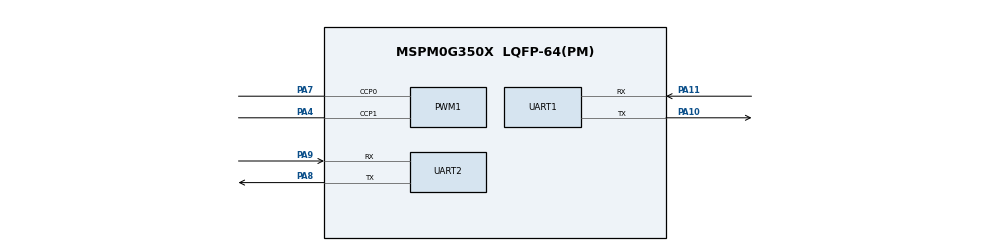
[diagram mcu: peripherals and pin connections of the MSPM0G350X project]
/**
 * @cliArgs --device "MSPM0G350X" --part "Default" --package "LQFP-64(PM)" --product "mspm0_sdk@2.10.00.04"
 * @versions {"tool":"1.27.0+4565"}
 */

/**
 * Import the modules used in this configuration.
 */
const GPIO    = scripting.addModule("/ti/driverlib/GPIO", {}, false);
const GPIO1   = GPIO.addInstance();
const GPIO2   = GPIO.addInstance();
const GPIO3   = GPIO.addInstance();
const GPIO4   = GPIO.addInstance();
const PWM     = scripting.addModule("/ti/driverlib/PWM", {}, false);
const PWM1    = PWM.addInstance();
const SYSCTL  = scripting.addModule("/ti/driverlib/SYSCTL");
const SYSTICK = scripting.addModule("/ti/driverlib/SYSTICK");
const TIMER   = scripting.addModule("/ti/driverlib/TIMER", {}, false);
const TIMER1  = TIMER.addInstance();
const UART    = scripting.addModule("/ti/driverlib/UART", {}, false);
const UART1   = UART.addInstance();
const UART2   = UART.addInstance();

/**
 * Write custom configuration values to the imported modules.
 */
const divider6       = system.clockTree["PLL_CLK2X_DIV"];
divider6.divideValue = 4;

const divider7       = system.clockTree["PLL_PDIV"];
divider7.divideValue = 2;

const divider9       = system.clockTree["UDIV"];
divider9.divideValue = 2;

const gate7  = system.clockTree["MFCLKGATE"];
gate7.enable = true;

const multiplier2         = system.clockTree["PLL_QDIV"];
multiplier2.multiplyValue = 10;

const mux8       = system.clockTree["HSCLKMUX"];
mux8.inputSelect = "HSCLKMUX_SYSPLL2X";

GPIO1.$name                              = "GPIO_BEEP";
GPIO1.port                               = "PORTA";
GPIO1.associatedPins[0].$name            = "USER_BEEP";
GPIO1.associatedPins[0].assignedPin      = "27";
GPIO1.associatedPins[0].internalResistor = "PULL_DOWN";

const Board = scripting.addModule("/ti/driverlib/Board", {}, false);

GPIO2.$name                              = "GPIO_LEDS";
GPIO2.port                               = "PORTB";
GPIO2.associatedPins[0].$name            = "USER_LED_G";
GPIO2.associatedPins[0].assignedPin      = "27";
GPIO2.associatedPins[0].internalResistor = "PULL_DOWN";

GPIO3.$name                          = "GPIO_MOTOR_DIR";
GPIO3.associatedPins.create(2);
GPIO3.associatedPins[0].$name        = "MOTOR_A_DIR";
GPIO3.associatedPins[0].assignedPort = "PORTA";
GPIO3.associatedPins[0].assignedPin  = "3";
GPIO3.associatedPins[1].$name        = "MOTOR_B_DIR";
GPIO3.associatedPins[1].assignedPort = "PORTB";
GPIO3.associatedPins[1].assignedPin  = "14";

GPIO4.$name                               = "GPIO_ENCODER";
GPIO4.associatedPins.create(4);
GPIO4.associatedPins[0].$name             = "E1B";
GPIO4.associatedPins[0].direction         = "INPUT";
GPIO4.associatedPins[0].assignedPort      = "PORTB";
GPIO4.associatedPins[0].assignedPin       = "20";
GPIO4.associatedPins[0].interruptEn       = true;
GPIO4.associatedPins[0].interruptPriority = "0";
GPIO4.associatedPins[0].polarity          = "RISE";
GPIO4.associatedPins[1].$name             = "E2B";
GPIO4.associatedPins[1].direction         = "INPUT";
GPIO4.associatedPins[1].assignedPort      = "PORTB";
GPIO4.associatedPins[1].assignedPin       = "25";
GPIO4.associatedPins[1].interruptEn       = true;
GPIO4.associatedPins[1].interruptPriority = "0";
GPIO4.associatedPins[1].polarity          = "RISE";
GPIO4.associatedPins[2].$name             = "E1A";
GPIO4.associatedPins[2].assignedPort      = "PORTB";
GPIO4.associatedPins[2].assignedPin       = "21";
GPIO4.associatedPins[2].direction         = "INPUT";
GPIO4.associatedPins[2].interruptEn       = true;
GPIO4.associatedPins[2].interruptPriority = "0";
GPIO4.associatedPins[2].polarity          = "RISE";
GPIO4.associatedPins[3].$name             = "E2A";
GPIO4.associatedPins[3].assignedPort      = "PORTB";
GPIO4.associatedPins[3].assignedPin       = "26";
GPIO4.associatedPins[3].direction         = "INPUT";
GPIO4.associatedPins[3].interruptEn       = true;
GPIO4.associatedPins[3].interruptPriority = "0";
GPIO4.associatedPins[3].polarity          = "RISE";

PWM1.clockDivider                       = 8;
PWM1.timerStartTimer                    = true;
PWM1.$name                              = "PWM_MOTOR";
PWM1.peripheral.ccp0Pin.$assign         = "PA7";
PWM1.peripheral.ccp1Pin.$assign         = "PA4";
PWM1.PWM_CHANNEL_0.$name                = "ti_driverlib_pwm_PWMTimerCC0";
PWM1.PWM_CHANNEL_0.invert               = true;
PWM1.PWM_CHANNEL_1.$name                = "ti_driverlib_pwm_PWMTimerCC1";
PWM1.PWM_CHANNEL_1.invert               = true;
PWM1.ccp0PinConfig.direction            = scripting.forceWrite("OUTPUT");
PWM1.ccp0PinConfig.hideOutputInversion  = scripting.forceWrite(false);
PWM1.ccp0PinConfig.onlyInternalResistor = scripting.forceWrite(false);
PWM1.ccp0PinConfig.passedPeripheralType = scripting.forceWrite("Digital");
PWM1.ccp0PinConfig.$name                = "ti_driverlib_gpio_GPIOPinGeneric0";
PWM1.ccp1PinConfig.direction            = scripting.forceWrite("OUTPUT");
PWM1.ccp1PinConfig.hideOutputInversion  = scripting.forceWrite(false);
PWM1.ccp1PinConfig.onlyInternalResistor = scripting.forceWrite(false);
PWM1.ccp1PinConfig.passedPeripheralType = scripting.forceWrite("Digital");
PWM1.ccp1PinConfig.$name                = "ti_driverlib_gpio_GPIOPinGeneric1";

SYSCTL.forceDefaultClkConfig = true;
SYSCTL.clockTreeEn           = true;

SYSTICK.periodEnable      = true;
SYSTICK.period            = 80000;
SYSTICK.interruptEnable   = true;
SYSTICK.interruptPriority = "0";
SYSTICK.systickEnable     = true;

TIMER1.$name             = "CLOCK";
TIMER1.timerClkDiv       = 8;
TIMER1.timerClkPrescale  = 100;
TIMER1.interrupts        = ["ZERO"];
TIMER1.timerStartTimer   = true;
TIMER1.timerMode         = "PERIODIC";
TIMER1.timerPeriod       = "20 ms";
TIMER1.interruptPriority = "3";

UART1.$name                                = "UART_CAM";
UART1.uartClkSrc                           = "MFCLK";
UART1.enabledInterrupts                    = ["DMA_DONE_RX"];
UART1.enabledDMARXTriggers                 = "DL_UART_DMA_INTERRUPT_RX";
UART1.peripheral.rxPin.$assign             = "PA11";
UART1.peripheral.txPin.$assign             = "PA10";
UART1.txPinConfig.direction                = scripting.forceWrite("OUTPUT");
UART1.txPinConfig.hideOutputInversion      = scripting.forceWrite(false);
UART1.txPinConfig.onlyInternalResistor     = scripting.forceWrite(false);
UART1.txPinConfig.passedPeripheralType     = scripting.forceWrite("Digital");
UART1.txPinConfig.$name                    = "ti_driverlib_gpio_GPIOPinGeneric2";
UART1.rxPinConfig.hideOutputInversion      = scripting.forceWrite(false);
UART1.rxPinConfig.onlyInternalResistor     = scripting.forceWrite(false);
UART1.rxPinConfig.passedPeripheralType     = scripting.forceWrite("Digital");
UART1.rxPinConfig.$name                    = "ti_driverlib_gpio_GPIOPinGeneric3";
UART1.DMA_CHANNEL_RX.$name                 = "DMA_UART0_RX";
UART1.DMA_CHANNEL_RX.addressMode           = "f2b";
UART1.DMA_CHANNEL_RX.srcLength             = "BYTE";
UART1.DMA_CHANNEL_RX.dstLength             = "BYTE";
UART1.DMA_CHANNEL_RX.configureTransferSize = true;
UART1.DMA_CHANNEL_RX.transferSize          = 12;

UART2.$name                            = "UART_IMU";
UART2.uartClkSrc                       = "MFCLK";
UART2.enabledInterrupts                = ["RX"];
UART2.peripheral.$assign               = "UART1";
UART2.peripheral.rxPin.$assign         = "PA9";
UART2.peripheral.txPin.$assign         = "PA8";
UART2.txPinConfig.direction            = scripting.forceWrite("OUTPUT");
UART2.txPinConfig.hideOutputInversion  = scripting.forceWrite(false);
UART2.txPinConfig.onlyInternalResistor = scripting.forceWrite(false);
UART2.txPinConfig.passedPeripheralType = scripting.forceWrite("Digital");
UART2.txPinConfig.$name                = "ti_driverlib_gpio_GPIOPinGeneric4";
UART2.rxPinConfig.hideOutputInversion  = scripting.forceWrite(false);
UART2.rxPinConfig.onlyInternalResistor = scripting.forceWrite(false);
UART2.rxPinConfig.passedPeripheralType = scripting.forceWrite("Digital");
UART2.rxPinConfig.$name                = "ti_driverlib_gpio_GPIOPinGeneric5";

/**
 * Pinmux solution for unlocked pins/peripherals. This ensures that minor changes to the automatic solver in a future
 * version of the tool will not impact the pinmux you originally saw.  These lines can be completely deleted in order to
 * re-solve from scratch.
 */
GPIO1.associatedPins[0].pin.$suggestSolution     = "PA27";
Board.peripheral.$suggestSolution                = "DEBUGSS";
Board.peripheral.swclkPin.$suggestSolution       = "PA20";
Board.peripheral.swdioPin.$suggestSolution       = "PA19";
GPIO2.associatedPins[0].pin.$suggestSolution     = "PB27";
GPIO3.associatedPins[0].pin.$suggestSolution     = "PA3";
GPIO3.associatedPins[1].pin.$suggestSolution     = "PB14";
GPIO4.associatedPins[0].pin.$suggestSolution     = "PB20";
GPIO4.associatedPins[1].pin.$suggestSolution     = "PB25";
GPIO4.associatedPins[2].pin.$suggestSolution     = "PB21";
GPIO4.associatedPins[3].pin.$suggestSolution     = "PB26";
PWM1.peripheral.$suggestSolution                 = "TIMG8";
TIMER1.peripheral.$suggestSolution               = "TIMA0";
UART1.peripheral.$suggestSolution                = "UART0";
UART1.DMA_CHANNEL_RX.peripheral.$suggestSolution = "DMA_CH0";
